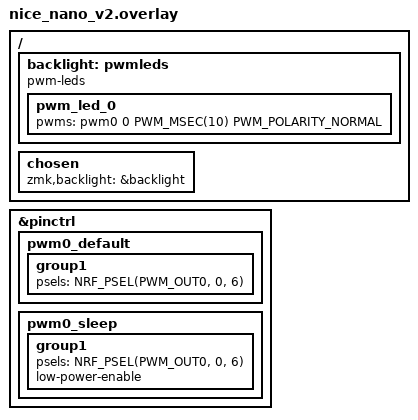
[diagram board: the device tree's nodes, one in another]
#include <dt-bindings/led/led.h>

&pinctrl {
    // Other pinctrl definitions for other hardware
    pwm0_default: pwm0_default {
        group1 {
            psels = <NRF_PSEL(PWM_OUT0, 0, 6)>;
        };
    };
    pwm0_sleep: pwm0_sleep {
        group1 {
            psels = <NRF_PSEL(PWM_OUT0, 0, 6)>;
            low-power-enable;
        };
    };
};

/ {
    backlight: pwmleds {
        compatible = "pwm-leds";
        pwm_led_0: pwm_led_0 {
            pwms = <&pwm0 0 PWM_MSEC(10) PWM_POLARITY_NORMAL>;
        };
    };
};

/ {
	chosen {
		 zmk,backlight = &backlight;
	};
};
